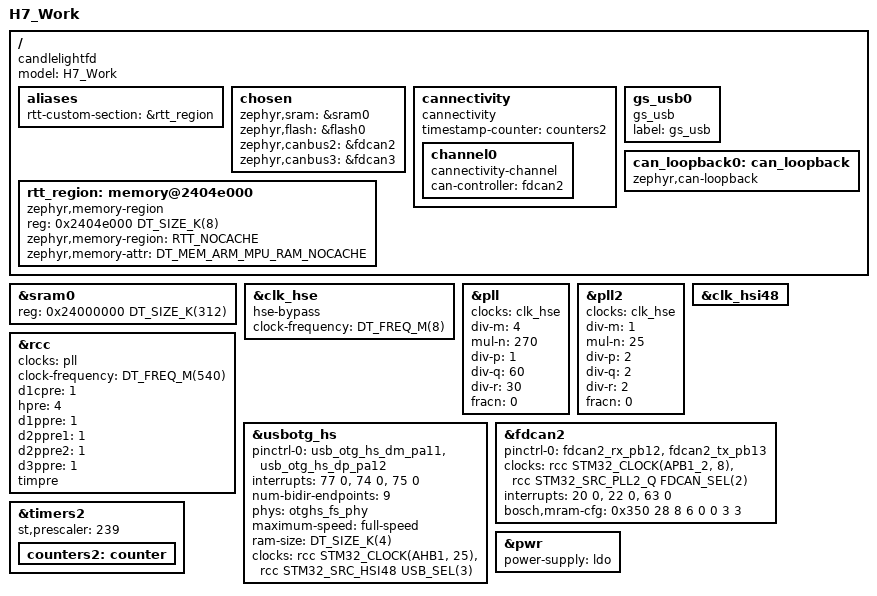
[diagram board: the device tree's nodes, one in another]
/dts-v1/;

#include <st/h7/stm32h723Xg.dtsi>
#include <st/h7/stm32h723vgtx-pinctrl.dtsi>
#include <zephyr/dt-bindings/memory-attr/memory-attr-arm.h>

/ {
	model = "H7_Work";
	compatible = "candlelightfd";

	aliases {
		rtt-custom-section = &rtt_region;
	};

	chosen {
		zephyr,sram = &sram0;
		zephyr,flash = &flash0;
		zephyr,canbus2 = &fdcan2;
		zephyr,canbus3 = &fdcan3;
	};

	cannectivity: cannectivity {
		compatible = "cannectivity";
		timestamp-counter = <&counters2>;

		channel0 {
			compatible = "cannectivity-channel";
			can-controller = <&fdcan2>;
		};
	};

	gs_usb0: gs_usb0 {
		compatible = "gs_usb";
		label = "gs_usb";
	};

	can_loopback0: can_loopback {
		compatible = "zephyr,can-loopback";
		status = "okay";
	};

	rtt_region: memory@2404e000 {
		compatible = "zephyr,memory-region", "mmio-sram";
		reg = <0x2404e000 DT_SIZE_K(8)>;
		zephyr,memory-region = "RTT_NOCACHE";
		zephyr,memory-attr = <DT_MEM_ARM_MPU_RAM_NOCACHE>;
	};
};

&sram0 {
	reg = <0x24000000 DT_SIZE_K(312)>;
};

/* Adjust the pll for a SYSTEM Clock of 480 MHz  */
&clk_hse {
	hse-bypass;
	clock-frequency = <DT_FREQ_M(8)>;
	status = "okay";
};

&pll {
	clocks = <&clk_hse>;
	div-m = <4>;   // 2 MHz to PLL（VCO）
	mul-n = <270>; // 540MHz
	div-p = <1>;   // 540MHz to SYS
	div-q = <60>;  // 90 MHz
	div-r = <30>;  // 180MHz to UART234578
	fracn = <0>;
	status = "okay";
};

&pll2 {
	clocks = <&clk_hse>;
	div-m = <1>;  // 8   MHz to PLL2（VCO）
	mul-n = <25>; // 200 MHz
	div-p = <2>;  // 100 MHz
	div-q = <2>;  // 100 MHz to FDCAN
	div-r = <2>;  // 100 MHz
	fracn = <0>;
	status = "okay";
};

&rcc {
	clocks = <&pll>;
	clock-frequency = <DT_FREQ_M(540)>;     /* 540 MHz SCLK*/
	d1cpre = <1>;                           /* 540 MHz CPU Clocks*/
	hpre = <4>;				/* 135 MHz */
	d1ppre = <1>;				/* 135 MHz APB3 Peripheral Clock */
	d2ppre1 = <1>;				/* 135 MHz APB1 Peripheral Clock */
	d2ppre2 = <1>;				/* 135 MHz APB2 Peripheral Clock */
	d3ppre = <1>;				/* 135 MHz APB4 Peripheral Clock */
	timpre;					/* Timer Clock Prescaler */
};

&clk_hsi48 {
	status = "okay";
};

zephyr_udc0: &usbotg_hs {
	pinctrl-0 = <&usb_otg_hs_dm_pa11 &usb_otg_hs_dp_pa12>;
	pinctrl-names = "default";
	/*           otghs   ep1_out ep1_in  */
	interrupts = <77 0>, <74 0>, <75 0>;
	num-bidir-endpoints = <9>;
	phys = <&otghs_fs_phy>;
	maximum-speed = "full-speed";
	ram-size = <DT_SIZE_K(4)>;
	clocks = <&rcc STM32_CLOCK(AHB1, 25)>,
		 <&rcc STM32_SRC_HSI48 USB_SEL(3)>;
	status = "okay";
};

&fdcan2 {
	pinctrl-0 = <&fdcan2_rx_pb12 &fdcan2_tx_pb13>;
	pinctrl-names = "default";
	clocks = <&rcc STM32_CLOCK(APB1_2, 8)>,
		 <&rcc STM32_SRC_PLL2_Q FDCAN_SEL(2)>;
	/*             int0   int1    calib  */
	interrupts = <20 0>, <22 0>, <63 0>;
	bosch,mram-cfg = <0x350 28 8 6 0 0 3 3>;
	status = "okay";
};

&timers2 {
	status = "okay";
	st,prescaler = <239>;

	counters2: counter {
		status = "okay";
	};
};

&pwr {
	power-supply = "ldo";
};
